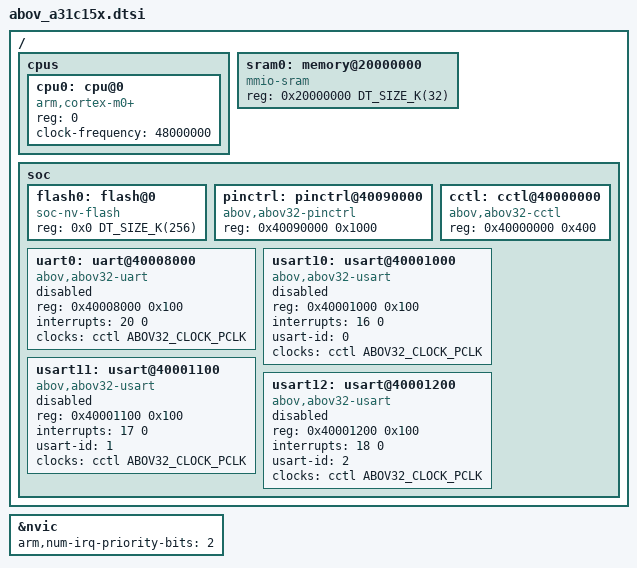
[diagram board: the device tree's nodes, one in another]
/*
 * Copyright (c) 2026 ABOV Semiconductor Co., Ltd.
 *
 * SPDX-License-Identifier: BSD-3-Clause
 */

#include <arm/armv6-m.dtsi>
#include <zephyr/dt-bindings/clock/abov32-clock.h>
#include <mem.h>

/ {
	cpus {
		#address-cells = <1>;
		#size-cells = <0>;

		cpu0: cpu@0 {
			device_type = "cpu";
			compatible = "arm,cortex-m0+";
			reg = <0>;
                        clock-frequency = <48000000>;
		};
	};

	sram0: memory@20000000 {
		compatible = "mmio-sram";
		reg = <0x20000000 DT_SIZE_K(32)>;
	};

	soc {
		flash0: flash@0 {
			compatible = "soc-nv-flash";
			reg = <0x0 DT_SIZE_K(256)>;
		};

		pinctrl: pinctrl@40090000 {
			compatible = "abov,abov32-pinctrl";
			reg = <0x40090000 0x1000>;
		};

		cctl: cctl@40000000 {
			compatible = "abov,abov32-cctl";
			reg = <0x40000000 0x400>;
			#clock-cells = <1>;
		};

		uart0: uart@40008000 {
			compatible = "abov,abov32-uart";
			reg = <0x40008000 0x100>;
			interrupts = <20 0>;
			clocks = <&cctl ABOV32_CLOCK_PCLK>;
			status = "disabled";
		};

		usart10: usart@40001000 {
			compatible = "abov,abov32-usart";
			reg = <0x40001000 0x100>;
			interrupts = <16 0>;
			usart-id = <0>;
			clocks = <&cctl ABOV32_CLOCK_PCLK>;
			status = "disabled";
		};

		usart11: usart@40001100 {
			compatible = "abov,abov32-usart";
			reg = <0x40001100 0x100>;
			interrupts = <17 0>;
			usart-id = <1>;
			clocks = <&cctl ABOV32_CLOCK_PCLK>;
			status = "disabled";
		};

		usart12: usart@40001200 {
			compatible = "abov,abov32-usart";
			reg = <0x40001200 0x100>;
			interrupts = <18 0>;
			usart-id = <2>;
			clocks = <&cctl ABOV32_CLOCK_PCLK>;
			status = "disabled";
		};
	};
};

&nvic {
	arm,num-irq-priority-bits = <2>;
};
